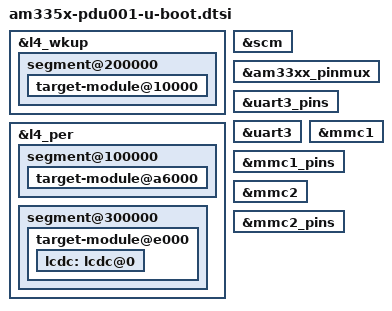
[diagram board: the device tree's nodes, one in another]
// SPDX-License-Identifier: GPL-2.0+
/*
 * Copyright (C) 2018 EETS GmbH - https://www.eets.ch/
 */

#include "am33xx-u-boot.dtsi"

&l4_wkup {
	u-boot,dm-all;
	segment@200000 {

		target-module@10000 {
			u-boot,dm-all;
		};
	};
};

&l4_per {
	u-boot,dm-all;
	segment@100000 {
		u-boot,dm-all;

		target-module@a6000 {
			u-boot,dm-all;
		};
	};

	segment@300000 {

		target-module@e000 {
			u-boot,dm-all;

			lcdc: lcdc@0 {
				u-boot,dm-all;
			};
		};
	};
};

&scm {
	u-boot,dm-all;
};

&am33xx_pinmux {
	u-boot,dm-all;
};

&uart3_pins {
	u-boot,dm-all;
};

&uart3 {
	u-boot,dm-all;
};

&mmc1 {
	u-boot,dm-all;
};

&mmc1_pins {
	u-boot,dm-all;
};

&mmc2 {
	u-boot,dm-all;
};

&mmc2_pins {
	u-boot,dm-all;
};
